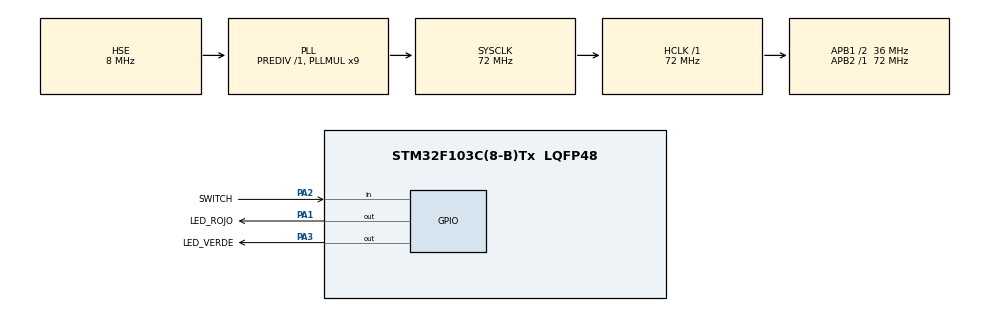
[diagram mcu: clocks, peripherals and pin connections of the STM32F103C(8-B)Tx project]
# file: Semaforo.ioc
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Mcu.Family=STM32F1
Mcu.Name=STM32F103C(8-B)Tx
Mcu.Package=LQFP48
NVIC.PriorityGroup=NVIC_PRIORITYGROUP_4
PA1.GPIO_Label=LED_ROJO
PA1.Signal=GPIO_Output
PA13.Mode=Serial_Wire
PA13.Signal=SYS_JTMS-SWDIO
PA14.Mode=Serial_Wire
PA14.Signal=SYS_JTCK-SWCLK
PA2.GPIO_Label=SWITCH
PA2.GPIO_PuPd=GPIO_PULLUP
PA2.Signal=GPIO_Input
PA3.GPIO_Label=LED_VERDE
PA3.Signal=GPIO_Output
PD0-OSC_IN.Mode=HSE-External-Oscillator
PD0-OSC_IN.Signal=RCC_OSC_IN
PD1-OSC_OUT.Mode=HSE-External-Oscillator
PD1-OSC_OUT.Signal=RCC_OSC_OUT
ProjectManager.HeapSize=0x200
ProjectManager.StackSize=0x400
ProjectManager.TargetToolchain=STM32CubeIDE
RCC.AHBFreq_Value=72000000
RCC.APB1CLKDivider=RCC_HCLK_DIV2
RCC.APB1Freq_Value=36000000
RCC.APB1TimFreq_Value=72000000
RCC.APB2Freq_Value=72000000
RCC.APB2TimFreq_Value=72000000
RCC.HCLKFreq_Value=72000000
RCC.PLLMUL=RCC_PLL_MUL9
RCC.PLLSourceVirtual=RCC_PLLSOURCE_HSE
RCC.SYSCLKFreq_VALUE=72000000
RCC.SYSCLKSource=RCC_SYSCLKSOURCE_PLLCLK
RCC.USBFreq_Value=72000000
board=custom

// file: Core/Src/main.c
/* USER CODE BEGIN Header */
/**
  ******************************************************************************
  * @file           : main.c
  * @brief          : Main program body
  ******************************************************************************
  * @attention
  *
  * Este código está basado en una FSM para un semáforo controlado por un botón.
  *
  ******************************************************************************
  */
/* USER CODE END Header */
#include "main.h"
#include "estados.h"

void SystemClock_Config(void);
static void MX_GPIO_Init(void);

int main(void)
{

  /* MCU Configuration--------------------------------------------------------*/

  /* Reset of all peripherals, Initializes the Flash interface and the Systick. */
  HAL_Init();

  /* Configure the system clock */
  SystemClock_Config();

  /* Initialize all configured peripherals */
  MX_GPIO_Init();
  /* USER CODE BEGIN 2 */
  // Estado inicial: LED verde encendido
  HAL_GPIO_WritePin(LED_VERDE_PORT, LED_VERDE_PIN, GPIO_PIN_SET);
  HAL_GPIO_WritePin(LED_ROJO_PORT, LED_ROJO_PIN, GPIO_PIN_RESET);
  /* USER CODE END 2 */

  /* Infinite loop */
  while (1)
  {
      // Leer el estado del botón (con debounce simple)
      if (is_button_pressed() && !boton_presionado) {
          boton_presionado = true;
          if (estado_actual == VERDE) {
              cambiar_estado(VERDE_PARPADEANTE);
          }
      } else if (!is_button_pressed()) {
          boton_presionado = false;
      }

      // Manejo de estados basado en tiempo
      manejar_temporizador();

      // Manejo del parpadeo (sin delay)
      if (estado_actual == VERDE_PARPADEANTE || estado_actual == ROJO_PARPADEANTE) {
          manejar_parpadeo();
      }
  }
}

void SystemClock_Config(void)
{
  RCC_OscInitTypeDef RCC_OscInitStruct = {0};
  RCC_ClkInitTypeDef RCC_ClkInitStruct = {0};

  /** Initializes the RCC Oscillators according to the specified parameters
  * in the RCC_OscInitTypeDef structure.
  */
  RCC_OscInitStruct.OscillatorType = RCC_OSCILLATORTYPE_HSE;
  RCC_OscInitStruct.HSEState = RCC_HSE_ON;
  RCC_OscInitStruct.HSEPredivValue = RCC_HSE_PREDIV_DIV1;
  RCC_OscInitStruct.HSIState = RCC_HSI_ON;
  RCC_OscInitStruct.PLL.PLLState = RCC_PLL_ON;
  RCC_OscInitStruct.PLL.PLLSource = RCC_PLLSOURCE_HSE;
  RCC_OscInitStruct.PLL.PLLMUL = RCC_PLL_MUL9;
  if (HAL_RCC_OscConfig(&RCC_OscInitStruct) != HAL_OK)
  {
    Error_Handler();
  }

  /** Initializes the CPU, AHB and APB buses clocks
  */
  RCC_ClkInitStruct.ClockType = RCC_CLOCKTYPE_HCLK|RCC_CLOCKTYPE_SYSCLK
                              |RCC_CLOCKTYPE_PCLK1|RCC_CLOCKTYPE_PCLK2;
  RCC_ClkInitStruct.SYSCLKSource = RCC_SYSCLKSOURCE_PLLCLK;
  RCC_ClkInitStruct.AHBCLKDivider = RCC_SYSCLK_DIV1;
  RCC_ClkInitStruct.APB1CLKDivider = RCC_HCLK_DIV2;
  RCC_ClkInitStruct.APB2CLKDivider = RCC_HCLK_DIV1;

  if (HAL_RCC_ClockConfig(&RCC_ClkInitStruct, FLASH_LATENCY_2) != HAL_OK)
  {
    Error_Handler();
  }
}

static void MX_GPIO_Init(void)
{
  GPIO_InitTypeDef GPIO_InitStruct = {0};

  /* GPIO Ports Clock Enable */
  __HAL_RCC_GPIOD_CLK_ENABLE();
  __HAL_RCC_GPIOA_CLK_ENABLE();

  /*Configure GPIO pin Output Level */
  HAL_GPIO_WritePin(GPIOA, LED_ROJO_Pin|LED_VERDE_Pin, GPIO_PIN_RESET);

  /*Configure GPIO pins : LED_ROJO_Pin LED_VERDE_Pin */
  GPIO_InitStruct.Pin = LED_ROJO_Pin|LED_VERDE_Pin;
  GPIO_InitStruct.Mode = GPIO_MODE_OUTPUT_PP;
  GPIO_InitStruct.Pull = GPIO_NOPULL;
  GPIO_InitStruct.Speed = GPIO_SPEED_FREQ_LOW;
  HAL_GPIO_Init(GPIOA, &GPIO_InitStruct);

  /*Configure GPIO pin : SWITCH_Pin */
  GPIO_InitStruct.Pin = SWITCH_Pin;
  GPIO_InitStruct.Mode = GPIO_MODE_INPUT;
  GPIO_InitStruct.Pull = GPIO_PULLUP;
  HAL_GPIO_Init(SWITCH_GPIO_Port, &GPIO_InitStruct);

}

void Error_Handler(void)
{
  __disable_irq();
  while (1)
  {
  }
}
